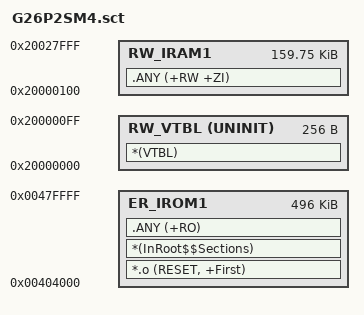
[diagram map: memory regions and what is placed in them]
; *************************************************************
; *** Scatter-Loading Description File generated by uVision ***
; *************************************************************

LR_IROM1 0x00404000 0x0007C000  {    ; load region size_region
  ER_IROM1 0x00404000 0x0007C000  {  ; load address = execution address
   *.o (RESET, +First)
   *(InRoot$$Sections)
   .ANY (+RO)
  }
  RW_VTBL 0x20000000 UNINIT 0x00000100  {  ; RW data
    *(VTBL)
  }
  RW_IRAM1 0x20000100 0x00027F00  {  ; RW data
   .ANY (+RW +ZI)
  }
}

